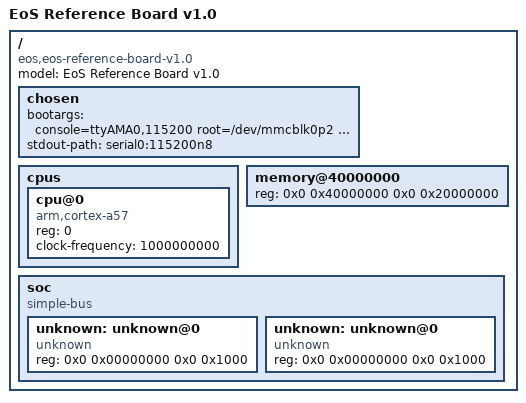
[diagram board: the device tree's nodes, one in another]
/dts-v1/;

/* EoS Generated Device Tree
 * Board:  EoS Reference Board v1.0 rev 1.0
 * CPU:    cortex-a57 (aarch64)
 * Tool:   ebuild cad_pipeline.py
 * DO NOT EDIT — regenerate from EoS Reference Board v1.0.kicad_pcb
 */

/ {
    #address-cells = <2>;
    #size-cells = <2>;
    compatible = "eos,eos-reference-board-v1.0";
    model = "EoS Reference Board v1.0";

    chosen {
        bootargs = "console=ttyAMA0,115200 root=/dev/mmcblk0p2 rw";
        stdout-path = "serial0:115200n8";
    };

    cpus {
        #address-cells = <1>;
        #size-cells = <0>;

        cpu@0 {
            device_type = "cpu";
            compatible = "arm,cortex-a57";
            reg = <0>;
            clock-frequency = <1000000000>;
        };
    };

    memory@40000000 {
        device_type = "memory";
        reg = <0x0 0x40000000 0x0 0x20000000>;
    };

    soc {
        #address-cells = <2>;
        #size-cells = <2>;
        compatible = "simple-bus";
        ranges;

        unknown: unknown@0 {
            compatible = "unknown";
            reg = <0x0 0x00000000 0x0 0x1000>;
            status = "okay";
        };

        unknown: unknown@0 {
            compatible = "unknown";
            reg = <0x0 0x00000000 0x0 0x1000>;
            status = "okay";
        };

        unknown: unknown@0 {
            compatible = "unknown";
            reg = <0x0 0x00000000 0x0 0x1000>;
            status = "okay";
        };

        unknown: unknown@0 {
            compatible = "unknown";
            reg = <0x0 0x00000000 0x0 0x1000>;
            status = "okay";
        };

        unknown: unknown@0 {
            compatible = "unknown";
            reg = <0x0 0x00000000 0x0 0x1000>;
            status = "okay";
        };

        unknown: unknown@0 {
            compatible = "unknown";
            reg = <0x0 0x00000000 0x0 0x1000>;
            status = "okay";
        };

        unknown: unknown@0 {
            compatible = "unknown";
            reg = <0x0 0x00000000 0x0 0x1000>;
            status = "okay";
        };

        unknown: unknown@0 {
            compatible = "unknown";
            reg = <0x0 0x00000000 0x0 0x1000>;
            status = "okay";
        };

    };
};
